VERSION "VUBR initial telemetry database"

NS_ :

BS_:

BU_: Vector__XXX AMS BMS VCU Inverter InverterCooling Precharge Dashboard PowerDistribution Pedalbox

BO_ 1 Error: 1 Vector__XXX
 SG_ error_code : 0|8@1+ (1,0) [0|255] "" Vector__XXX

BO_ 6 PrechargeStatus: 8 Precharge
 SG_ precharge_register M : 0|8@1+ (1,0) [0|255] "" Vector__XXX
 SG_ precharge_status m32 : 8|8@1+ (1,0) [0|255] "" Vector__XXX
 SG_ precharge_voltage_battery m48 : 8|8@1+ (1,0) [0|255] "V" Vector__XXX
 SG_ precharge_voltage_ts m64 : 8|8@1+ (1,0) [0|255] "V" Vector__XXX

BO_ 18 AppsAnalogValues: 8 VCU
 SG_ apps1_raw : 0|16@1+ (1,0) [0|65535] "" Vector__XXX
 SG_ apps2_raw : 16|16@1+ (1,0) [0|65535] "" Vector__XXX

BO_ 21 DashboardInfo: 1 Dashboard
 SG_ dashboard_event : 0|8@1+ (1,0) [0|255] "" Vector__XXX

BO_ 36 DtiSetAcCurrent: 8 Pedalbox
 SG_ inverter_cmd_target_ac_current : 7|16@0- (0.1,0) [-850|850] "A" Vector__XXX

BO_ 68 DtiSetBrakeCurrent: 8 Pedalbox
 SG_ inverter_cmd_target_brake_current : 7|16@0- (0.1,0) [0|850] "A" Vector__XXX

BO_ 100 DtiSetErpm: 4 Pedalbox
 SG_ inverter_cmd_target_speed : 7|32@0- (1,0) [-100000|100000] "ERPM" Vector__XXX

BO_ 132 DtiSetPosition: 2 Pedalbox
 SG_ inverter_cmd_target_position : 7|16@0- (0.1,0) [0|359] "deg" Vector__XXX

BO_ 164 DtiSetRelativeCurrent: 2 Pedalbox
 SG_ inverter_cmd_target_relative_current : 7|16@0- (0.1,0) [-100|100] "%" Vector__XXX

BO_ 196 DtiSetRelativeBrakeCurrent: 2 Pedalbox
 SG_ inverter_cmd_target_relative_brake_current : 7|16@0- (0.1,0) [0|100] "%" Vector__XXX

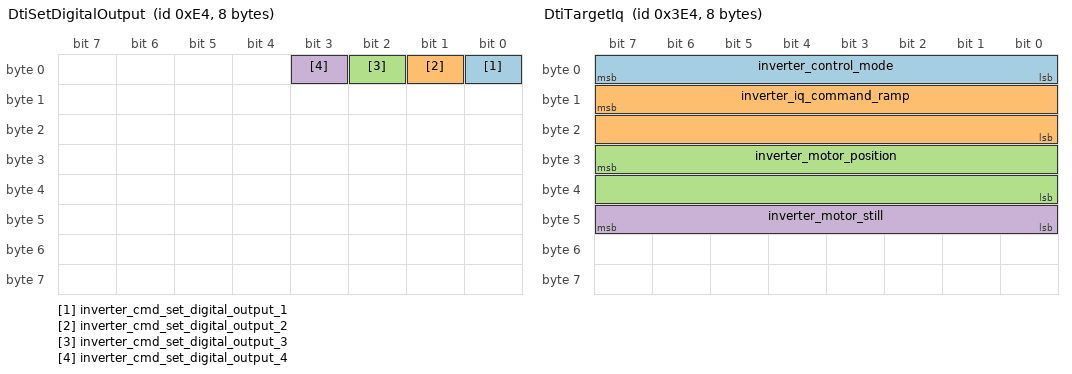
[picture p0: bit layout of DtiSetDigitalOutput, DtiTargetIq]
BO_ 228 DtiSetDigitalOutput: 8 Pedalbox
 SG_ inverter_cmd_set_digital_output_1 : 0|1@0+ (1,0) [0|1] "" Vector__XXX
 SG_ inverter_cmd_set_digital_output_2 : 1|1@0+ (1,0) [0|1] "" Vector__XXX
 SG_ inverter_cmd_set_digital_output_3 : 2|1@0+ (1,0) [0|1] "" Vector__XXX
 SG_ inverter_cmd_set_digital_output_4 : 3|1@0+ (1,0) [0|1] "" Vector__XXX

BO_ 260 DtiSetMaxAcCurrent: 2 Pedalbox
 SG_ inverter_cmd_max_ac_current : 7|16@0- (0.1,0) [0|850] "A" Vector__XXX

BO_ 292 DtiSetMaxAcBrakeCurrent: 2 Pedalbox
 SG_ inverter_cmd_max_ac_brake_current : 7|16@0- (0.1,0) [-850|0] "A" Vector__XXX

BO_ 324 DtiSetMaxDcCurrent: 2 Pedalbox
 SG_ inverter_cmd_max_dc_current : 7|16@0- (0.1,0) [0|850] "A" Vector__XXX

BO_ 356 DtiSetMaxDcBrakeCurrent: 2 Pedalbox
 SG_ inverter_cmd_max_dc_brake_current : 7|16@0- (0.1,0) [-850|0] "A" Vector__XXX

BO_ 388 DtiSetDriveEnable: 2 Pedalbox
 SG_ inverter_cmd_drive_enable : 7|8@0+ (1,0) [0|1] "" Vector__XXX

BO_ 996 DtiTargetIq: 8 Inverter
 SG_ inverter_control_mode : 7|8@0+ (1,0) [0|7] "" Vector__XXX
 SG_ inverter_iq_command_ramp : 15|16@0- (0.1,0) [-850|850] "A" Vector__XXX
 SG_ inverter_motor_position : 31|16@0+ (0.1,0) [0|359] "deg" Vector__XXX
 SG_ inverter_motor_still : 47|8@0+ (1,0) [0|1] "" Vector__XXX

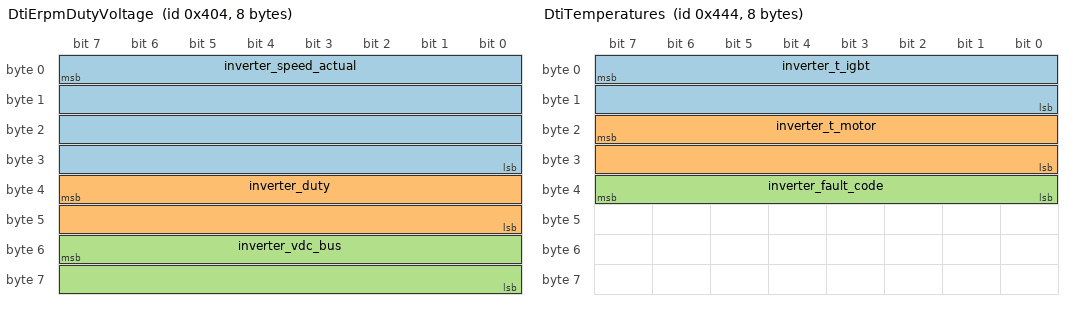
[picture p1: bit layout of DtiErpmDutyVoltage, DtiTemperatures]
BO_ 1028 DtiErpmDutyVoltage: 8 Inverter
 SG_ inverter_speed_actual : 7|32@0- (1,0) [-120000|120000] "ERPM" Vector__XXX
 SG_ inverter_duty : 39|16@0- (0.1,0) [-100|100] "%" Vector__XXX
 SG_ inverter_vdc_bus : 55|16@0- (1,0) [0|1000] "V" Vector__XXX

BO_ 1060 DtiAcDcCurrent: 8 Inverter
 SG_ inverter_ac_current : 7|16@0- (0.1,0) [-850|850] "A" Vector__XXX
 SG_ inverter_dc_current : 23|16@0- (0.1,0) [-850|850] "A" Vector__XXX

BO_ 1092 DtiTemperatures: 8 Inverter
 SG_ inverter_t_igbt : 7|16@0- (0.1,0) [-55|200] "degC" Vector__XXX
 SG_ inverter_t_motor : 23|16@0- (0.1,0) [-55|200] "degC" Vector__XXX
 SG_ inverter_fault_code : 39|8@0+ (1,0) [0|255] "" Vector__XXX

BO_ 1124 DtiFoc: 8 Inverter
 SG_ inverter_id_actual : 7|32@0- (0.01,0) [-850|850] "A" Vector__XXX
 SG_ inverter_iq_actual : 39|32@0- (0.01,0) [-850|850] "A" Vector__XXX

BO_ 1156 DtiMisc: 8 Inverter
 SG_ inverter_throttle : 7|8@0- (1,0) [0|100] "%" Vector__XXX
 SG_ inverter_brake : 15|8@0- (1,0) [0|100] "%" Vector__XXX
 SG_ inverter_digital_input_1 : 16|1@0+ (1,0) [0|1] "" Vector__XXX
 SG_ inverter_digital_input_2 : 17|1@0+ (1,0) [0|1] "" Vector__XXX
 SG_ inverter_digital_input_3 : 18|1@0+ (1,0) [0|1] "" Vector__XXX
 SG_ inverter_digital_input_4 : 19|1@0+ (1,0) [0|1] "" Vector__XXX
 SG_ inverter_digital_output_1 : 20|1@0+ (1,0) [0|1] "" Vector__XXX
 SG_ inverter_digital_output_2 : 21|1@0+ (1,0) [0|1] "" Vector__XXX
 SG_ inverter_digital_output_3 : 22|1@0+ (1,0) [0|1] "" Vector__XXX
 SG_ inverter_digital_output_4 : 23|1@0+ (1,0) [0|1] "" Vector__XXX
 SG_ inverter_drive_enable : 31|8@0+ (1,0) [0|1] "" Vector__XXX
 SG_ inverter_capacitor_temp_limit : 32|1@0+ (1,0) [0|1] "" Vector__XXX
 SG_ inverter_dc_current_limit : 33|1@0+ (1,0) [0|1] "" Vector__XXX
 SG_ inverter_drive_enable_limit : 34|1@0+ (1,0) [0|1] "" Vector__XXX
 SG_ inverter_igbt_accel_limit : 35|1@0+ (1,0) [0|1] "" Vector__XXX
 SG_ inverter_igbt_temp_limit : 36|1@0+ (1,0) [0|1] "" Vector__XXX
 SG_ inverter_input_voltage_limit : 37|1@0+ (1,0) [0|1] "" Vector__XXX
 SG_ inverter_motor_accel_limit : 38|1@0+ (1,0) [0|1] "" Vector__XXX
 SG_ inverter_motor_temp_limit : 39|1@0+ (1,0) [0|1] "" Vector__XXX
 SG_ inverter_rpm_min_limit : 40|1@0+ (1,0) [0|1] "" Vector__XXX
 SG_ inverter_rpm_max_limit : 41|1@0+ (1,0) [0|1] "" Vector__XXX
 SG_ inverter_power_limit : 42|1@0+ (1,0) [0|1] "" Vector__XXX
 SG_ inverter_can_map_version : 63|8@0+ (0.1,0) [0|255] "" Vector__XXX

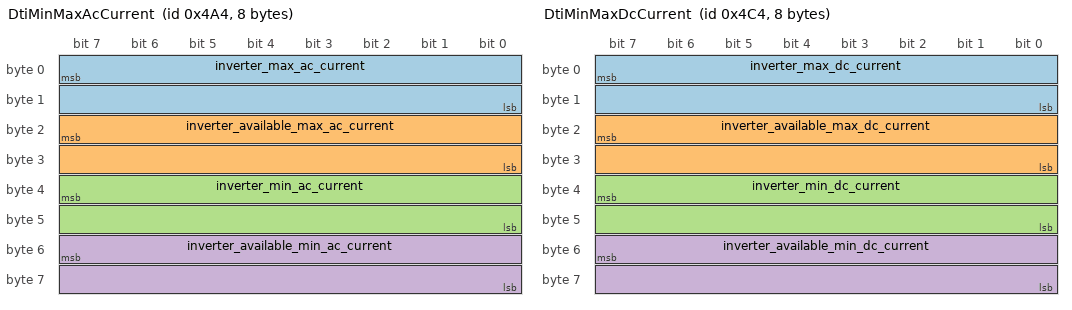
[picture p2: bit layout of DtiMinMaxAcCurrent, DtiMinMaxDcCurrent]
BO_ 1188 DtiMinMaxAcCurrent: 8 Inverter
 SG_ inverter_max_ac_current : 7|16@0- (0.1,0) [0|850] "A" Vector__XXX
 SG_ inverter_available_max_ac_current : 23|16@0- (0.1,0) [0|850] "A" Vector__XXX
 SG_ inverter_min_ac_current : 39|16@0- (0.1,0) [-850|0] "A" Vector__XXX
 SG_ inverter_available_min_ac_current : 55|16@0- (0.1,0) [-850|0] "A" Vector__XXX

BO_ 1220 DtiMinMaxDcCurrent: 8 Inverter
 SG_ inverter_max_dc_current : 7|16@0- (0.1,0) [0|850] "A" Vector__XXX
 SG_ inverter_available_max_dc_current : 23|16@0- (0.1,0) [0|850] "A" Vector__XXX
 SG_ inverter_min_dc_current : 39|16@0- (0.1,0) [-850|0] "A" Vector__XXX
 SG_ inverter_available_min_dc_current : 55|16@0- (0.1,0) [-850|0] "A" Vector__XXX

BO_ 768 UserStatus: 8 VCU
 SG_ user_register M : 0|8@1+ (1,0) [0|255] "" Vector__XXX
 SG_ user_brake m2 : 24|8@1+ (1,0) [0|255] "" Vector__XXX
 SG_ user_apps m2 : 8|16@1+ (1,0) [0|65535] "" Vector__XXX
 SG_ user_state m1 : 8|8@1+ (1,0) [0|255] "" Vector__XXX

BO_ 770 BRAKESENS1_AVAL_ID: 2 VCU
 SG_ brake_pressure_1 : 0|16@1+ (1,0) [0|65535] "raw" Vector__XXX

BO_ 771 BRAKESENS2_AVAL_ID: 2 VCU
 SG_ brake_pressure_2 : 0|16@1+ (1,0) [0|65535] "raw" Vector__XXX

BO_ 772 SdcStatus: 2 Vector__XXX
 SG_ sdc_index : 0|8@1+ (1,0) [0|255] "" Vector__XXX
 SG_ sdc_closed : 8|1@1+ (1,0) [0|1] "" Vector__XXX

BO_ 773 PedalboxStatus: 1 Pedalbox
 SG_ bspd_hard_braking : 0|1@1+ (1,0) [0|1] "" Vector__XXX

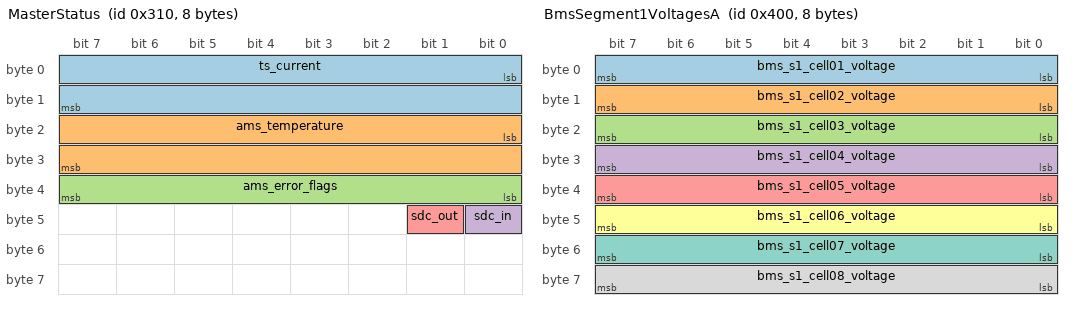
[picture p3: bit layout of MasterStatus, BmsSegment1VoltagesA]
BO_ 784 MasterStatus: 8 AMS
 SG_ ts_current : 0|16@1- (0.1,0) [-3276.8|3276.7] "A" Vector__XXX
 SG_ ams_temperature : 16|16@1- (0.1,0) [-3276.8|3276.7] "degC" Vector__XXX
 SG_ ams_error_flags : 32|8@1+ (1,0) [0|255] "" Vector__XXX
 SG_ sdc_in : 40|1@1+ (1,0) [0|1] "" Vector__XXX
 SG_ sdc_out : 41|1@1+ (1,0) [0|1] "" Vector__XXX

BO_ 1024 BmsSegment1VoltagesA: 8 AMS
 SG_ bms_s1_cell01_voltage : 0|8@1+ (0.01,2) [2|4.55] "V" Vector__XXX
 SG_ bms_s1_cell02_voltage : 8|8@1+ (0.01,2) [2|4.55] "V" Vector__XXX
 SG_ bms_s1_cell03_voltage : 16|8@1+ (0.01,2) [2|4.55] "V" Vector__XXX
 SG_ bms_s1_cell04_voltage : 24|8@1+ (0.01,2) [2|4.55] "V" Vector__XXX
 SG_ bms_s1_cell05_voltage : 32|8@1+ (0.01,2) [2|4.55] "V" Vector__XXX
 SG_ bms_s1_cell06_voltage : 40|8@1+ (0.01,2) [2|4.55] "V" Vector__XXX
 SG_ bms_s1_cell07_voltage : 48|8@1+ (0.01,2) [2|4.55] "V" Vector__XXX
 SG_ bms_s1_cell08_voltage : 56|8@1+ (0.01,2) [2|4.55] "V" Vector__XXX

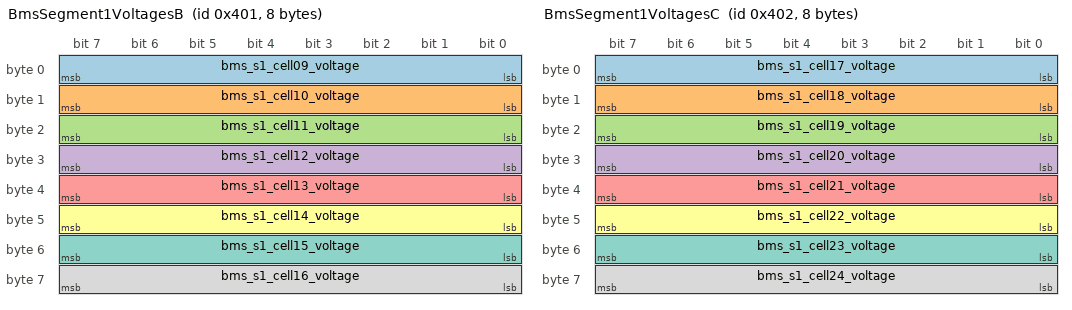
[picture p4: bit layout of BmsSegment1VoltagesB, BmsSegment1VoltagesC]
BO_ 1025 BmsSegment1VoltagesB: 8 AMS
 SG_ bms_s1_cell09_voltage : 0|8@1+ (0.01,2) [2|4.55] "V" Vector__XXX
 SG_ bms_s1_cell10_voltage : 8|8@1+ (0.01,2) [2|4.55] "V" Vector__XXX
 SG_ bms_s1_cell11_voltage : 16|8@1+ (0.01,2) [2|4.55] "V" Vector__XXX
 SG_ bms_s1_cell12_voltage : 24|8@1+ (0.01,2) [2|4.55] "V" Vector__XXX
 SG_ bms_s1_cell13_voltage : 32|8@1+ (0.01,2) [2|4.55] "V" Vector__XXX
 SG_ bms_s1_cell14_voltage : 40|8@1+ (0.01,2) [2|4.55] "V" Vector__XXX
 SG_ bms_s1_cell15_voltage : 48|8@1+ (0.01,2) [2|4.55] "V" Vector__XXX
 SG_ bms_s1_cell16_voltage : 56|8@1+ (0.01,2) [2|4.55] "V" Vector__XXX

BO_ 1026 BmsSegment1VoltagesC: 8 AMS
 SG_ bms_s1_cell17_voltage : 0|8@1+ (0.01,2) [2|4.55] "V" Vector__XXX
 SG_ bms_s1_cell18_voltage : 8|8@1+ (0.01,2) [2|4.55] "V" Vector__XXX
 SG_ bms_s1_cell19_voltage : 16|8@1+ (0.01,2) [2|4.55] "V" Vector__XXX
 SG_ bms_s1_cell20_voltage : 24|8@1+ (0.01,2) [2|4.55] "V" Vector__XXX
 SG_ bms_s1_cell21_voltage : 32|8@1+ (0.01,2) [2|4.55] "V" Vector__XXX
 SG_ bms_s1_cell22_voltage : 40|8@1+ (0.01,2) [2|4.55] "V" Vector__XXX
 SG_ bms_s1_cell23_voltage : 48|8@1+ (0.01,2) [2|4.55] "V" Vector__XXX
 SG_ bms_s1_cell24_voltage : 56|8@1+ (0.01,2) [2|4.55] "V" Vector__XXX

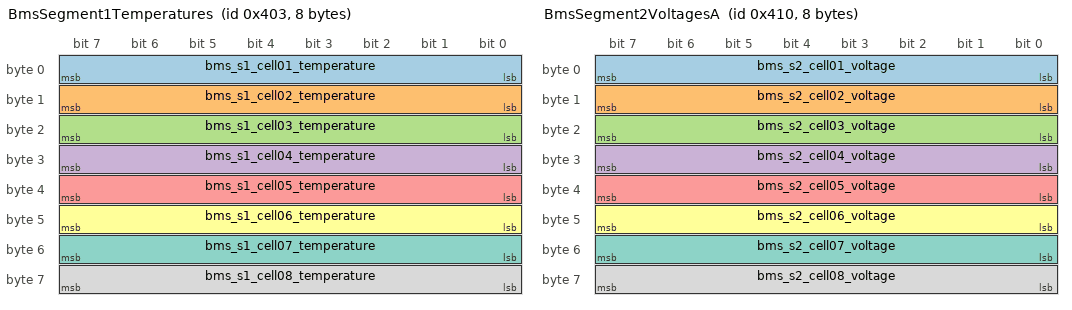
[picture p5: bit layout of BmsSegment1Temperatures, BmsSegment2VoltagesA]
BO_ 1027 BmsSegment1Temperatures: 8 AMS
 SG_ bms_s1_cell01_temperature : 0|8@1+ (0.5,-40) [-40|87.5] "degC" Vector__XXX
 SG_ bms_s1_cell02_temperature : 8|8@1+ (0.5,-40) [-40|87.5] "degC" Vector__XXX
 SG_ bms_s1_cell03_temperature : 16|8@1+ (0.5,-40) [-40|87.5] "degC" Vector__XXX
 SG_ bms_s1_cell04_temperature : 24|8@1+ (0.5,-40) [-40|87.5] "degC" Vector__XXX
 SG_ bms_s1_cell05_temperature : 32|8@1+ (0.5,-40) [-40|87.5] "degC" Vector__XXX
 SG_ bms_s1_cell06_temperature : 40|8@1+ (0.5,-40) [-40|87.5] "degC" Vector__XXX
 SG_ bms_s1_cell07_temperature : 48|8@1+ (0.5,-40) [-40|87.5] "degC" Vector__XXX
 SG_ bms_s1_cell08_temperature : 56|8@1+ (0.5,-40) [-40|87.5] "degC" Vector__XXX

BO_ 1029 BmsSegment1TemperaturesB: 2 AMS
 SG_ bms_s1_cell09_temperature : 0|8@1+ (0.5,-40) [-40|87.5] "degC" Vector__XXX
 SG_ bms_s1_cell10_temperature : 8|8@1+ (0.5,-40) [-40|87.5] "degC" Vector__XXX

BO_ 1040 BmsSegment2VoltagesA: 8 AMS
 SG_ bms_s2_cell01_voltage : 0|8@1+ (0.01,2) [2|4.55] "V" Vector__XXX
 SG_ bms_s2_cell02_voltage : 8|8@1+ (0.01,2) [2|4.55] "V" Vector__XXX
 SG_ bms_s2_cell03_voltage : 16|8@1+ (0.01,2) [2|4.55] "V" Vector__XXX
 SG_ bms_s2_cell04_voltage : 24|8@1+ (0.01,2) [2|4.55] "V" Vector__XXX
 SG_ bms_s2_cell05_voltage : 32|8@1+ (0.01,2) [2|4.55] "V" Vector__XXX
 SG_ bms_s2_cell06_voltage : 40|8@1+ (0.01,2) [2|4.55] "V" Vector__XXX
 SG_ bms_s2_cell07_voltage : 48|8@1+ (0.01,2) [2|4.55] "V" Vector__XXX
 SG_ bms_s2_cell08_voltage : 56|8@1+ (0.01,2) [2|4.55] "V" Vector__XXX

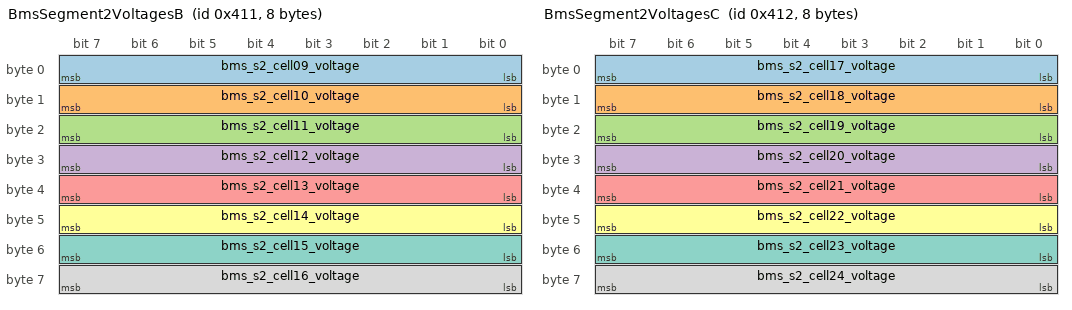
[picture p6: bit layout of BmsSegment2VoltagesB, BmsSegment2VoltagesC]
BO_ 1041 BmsSegment2VoltagesB: 8 AMS
 SG_ bms_s2_cell09_voltage : 0|8@1+ (0.01,2) [2|4.55] "V" Vector__XXX
 SG_ bms_s2_cell10_voltage : 8|8@1+ (0.01,2) [2|4.55] "V" Vector__XXX
 SG_ bms_s2_cell11_voltage : 16|8@1+ (0.01,2) [2|4.55] "V" Vector__XXX
 SG_ bms_s2_cell12_voltage : 24|8@1+ (0.01,2) [2|4.55] "V" Vector__XXX
 SG_ bms_s2_cell13_voltage : 32|8@1+ (0.01,2) [2|4.55] "V" Vector__XXX
 SG_ bms_s2_cell14_voltage : 40|8@1+ (0.01,2) [2|4.55] "V" Vector__XXX
 SG_ bms_s2_cell15_voltage : 48|8@1+ (0.01,2) [2|4.55] "V" Vector__XXX
 SG_ bms_s2_cell16_voltage : 56|8@1+ (0.01,2) [2|4.55] "V" Vector__XXX

BO_ 1042 BmsSegment2VoltagesC: 8 AMS
 SG_ bms_s2_cell17_voltage : 0|8@1+ (0.01,2) [2|4.55] "V" Vector__XXX
 SG_ bms_s2_cell18_voltage : 8|8@1+ (0.01,2) [2|4.55] "V" Vector__XXX
 SG_ bms_s2_cell19_voltage : 16|8@1+ (0.01,2) [2|4.55] "V" Vector__XXX
 SG_ bms_s2_cell20_voltage : 24|8@1+ (0.01,2) [2|4.55] "V" Vector__XXX
 SG_ bms_s2_cell21_voltage : 32|8@1+ (0.01,2) [2|4.55] "V" Vector__XXX
 SG_ bms_s2_cell22_voltage : 40|8@1+ (0.01,2) [2|4.55] "V" Vector__XXX
 SG_ bms_s2_cell23_voltage : 48|8@1+ (0.01,2) [2|4.55] "V" Vector__XXX
 SG_ bms_s2_cell24_voltage : 56|8@1+ (0.01,2) [2|4.55] "V" Vector__XXX

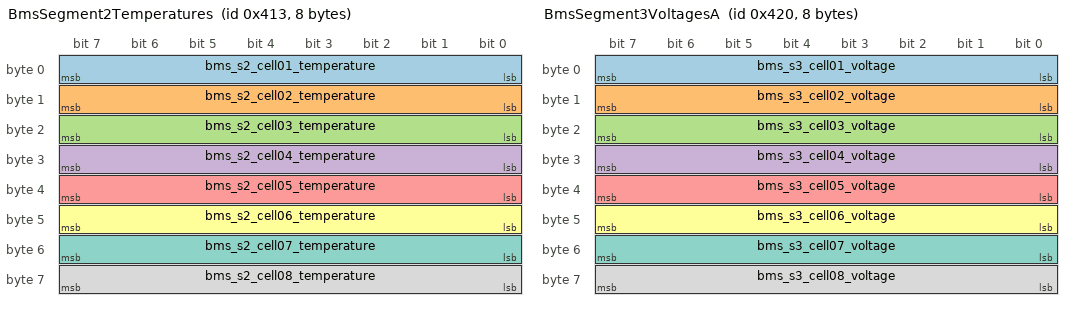
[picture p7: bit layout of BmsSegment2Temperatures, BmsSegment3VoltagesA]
BO_ 1043 BmsSegment2Temperatures: 8 AMS
 SG_ bms_s2_cell01_temperature : 0|8@1+ (0.5,-40) [-40|87.5] "degC" Vector__XXX
 SG_ bms_s2_cell02_temperature : 8|8@1+ (0.5,-40) [-40|87.5] "degC" Vector__XXX
 SG_ bms_s2_cell03_temperature : 16|8@1+ (0.5,-40) [-40|87.5] "degC" Vector__XXX
 SG_ bms_s2_cell04_temperature : 24|8@1+ (0.5,-40) [-40|87.5] "degC" Vector__XXX
 SG_ bms_s2_cell05_temperature : 32|8@1+ (0.5,-40) [-40|87.5] "degC" Vector__XXX
 SG_ bms_s2_cell06_temperature : 40|8@1+ (0.5,-40) [-40|87.5] "degC" Vector__XXX
 SG_ bms_s2_cell07_temperature : 48|8@1+ (0.5,-40) [-40|87.5] "degC" Vector__XXX
 SG_ bms_s2_cell08_temperature : 56|8@1+ (0.5,-40) [-40|87.5] "degC" Vector__XXX

BO_ 1045 BmsSegment2TemperaturesB: 2 AMS
 SG_ bms_s2_cell09_temperature : 0|8@1+ (0.5,-40) [-40|87.5] "degC" Vector__XXX
 SG_ bms_s2_cell10_temperature : 8|8@1+ (0.5,-40) [-40|87.5] "degC" Vector__XXX

BO_ 1056 BmsSegment3VoltagesA: 8 AMS
 SG_ bms_s3_cell01_voltage : 0|8@1+ (0.01,2) [2|4.55] "V" Vector__XXX
 SG_ bms_s3_cell02_voltage : 8|8@1+ (0.01,2) [2|4.55] "V" Vector__XXX
 SG_ bms_s3_cell03_voltage : 16|8@1+ (0.01,2) [2|4.55] "V" Vector__XXX
 SG_ bms_s3_cell04_voltage : 24|8@1+ (0.01,2) [2|4.55] "V" Vector__XXX
 SG_ bms_s3_cell05_voltage : 32|8@1+ (0.01,2) [2|4.55] "V" Vector__XXX
 SG_ bms_s3_cell06_voltage : 40|8@1+ (0.01,2) [2|4.55] "V" Vector__XXX
 SG_ bms_s3_cell07_voltage : 48|8@1+ (0.01,2) [2|4.55] "V" Vector__XXX
 SG_ bms_s3_cell08_voltage : 56|8@1+ (0.01,2) [2|4.55] "V" Vector__XXX

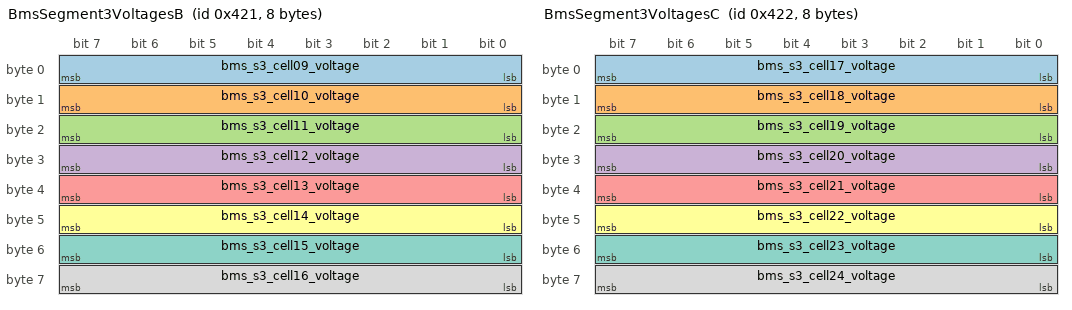
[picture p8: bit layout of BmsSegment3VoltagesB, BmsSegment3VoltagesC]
BO_ 1057 BmsSegment3VoltagesB: 8 AMS
 SG_ bms_s3_cell09_voltage : 0|8@1+ (0.01,2) [2|4.55] "V" Vector__XXX
 SG_ bms_s3_cell10_voltage : 8|8@1+ (0.01,2) [2|4.55] "V" Vector__XXX
 SG_ bms_s3_cell11_voltage : 16|8@1+ (0.01,2) [2|4.55] "V" Vector__XXX
 SG_ bms_s3_cell12_voltage : 24|8@1+ (0.01,2) [2|4.55] "V" Vector__XXX
 SG_ bms_s3_cell13_voltage : 32|8@1+ (0.01,2) [2|4.55] "V" Vector__XXX
 SG_ bms_s3_cell14_voltage : 40|8@1+ (0.01,2) [2|4.55] "V" Vector__XXX
 SG_ bms_s3_cell15_voltage : 48|8@1+ (0.01,2) [2|4.55] "V" Vector__XXX
 SG_ bms_s3_cell16_voltage : 56|8@1+ (0.01,2) [2|4.55] "V" Vector__XXX

BO_ 1058 BmsSegment3VoltagesC: 8 AMS
 SG_ bms_s3_cell17_voltage : 0|8@1+ (0.01,2) [2|4.55] "V" Vector__XXX
 SG_ bms_s3_cell18_voltage : 8|8@1+ (0.01,2) [2|4.55] "V" Vector__XXX
 SG_ bms_s3_cell19_voltage : 16|8@1+ (0.01,2) [2|4.55] "V" Vector__XXX
 SG_ bms_s3_cell20_voltage : 24|8@1+ (0.01,2) [2|4.55] "V" Vector__XXX
 SG_ bms_s3_cell21_voltage : 32|8@1+ (0.01,2) [2|4.55] "V" Vector__XXX
 SG_ bms_s3_cell22_voltage : 40|8@1+ (0.01,2) [2|4.55] "V" Vector__XXX
 SG_ bms_s3_cell23_voltage : 48|8@1+ (0.01,2) [2|4.55] "V" Vector__XXX
 SG_ bms_s3_cell24_voltage : 56|8@1+ (0.01,2) [2|4.55] "V" Vector__XXX

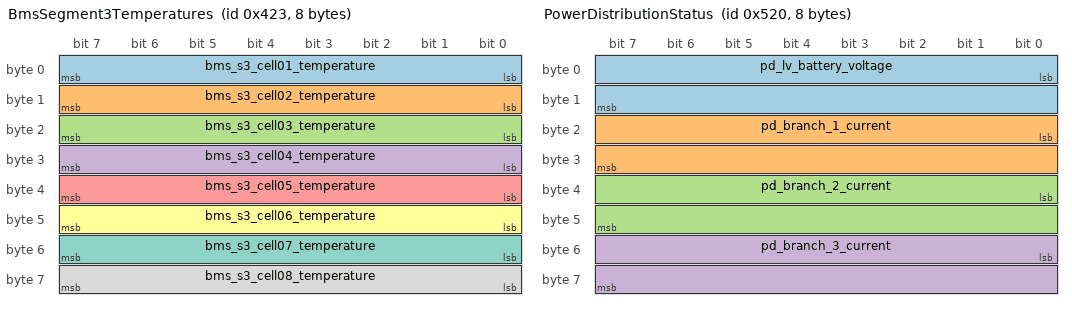
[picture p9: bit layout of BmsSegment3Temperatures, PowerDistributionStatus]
BO_ 1059 BmsSegment3Temperatures: 8 AMS
 SG_ bms_s3_cell01_temperature : 0|8@1+ (0.5,-40) [-40|87.5] "degC" Vector__XXX
 SG_ bms_s3_cell02_temperature : 8|8@1+ (0.5,-40) [-40|87.5] "degC" Vector__XXX
 SG_ bms_s3_cell03_temperature : 16|8@1+ (0.5,-40) [-40|87.5] "degC" Vector__XXX
 SG_ bms_s3_cell04_temperature : 24|8@1+ (0.5,-40) [-40|87.5] "degC" Vector__XXX
 SG_ bms_s3_cell05_temperature : 32|8@1+ (0.5,-40) [-40|87.5] "degC" Vector__XXX
 SG_ bms_s3_cell06_temperature : 40|8@1+ (0.5,-40) [-40|87.5] "degC" Vector__XXX
 SG_ bms_s3_cell07_temperature : 48|8@1+ (0.5,-40) [-40|87.5] "degC" Vector__XXX
 SG_ bms_s3_cell08_temperature : 56|8@1+ (0.5,-40) [-40|87.5] "degC" Vector__XXX

BO_ 1061 BmsSegment3TemperaturesB: 2 AMS
 SG_ bms_s3_cell09_temperature : 0|8@1+ (0.5,-40) [-40|87.5] "degC" Vector__XXX
 SG_ bms_s3_cell10_temperature : 8|8@1+ (0.5,-40) [-40|87.5] "degC" Vector__XXX

BO_ 1120 InverterCoolingStatus: 8 InverterCooling
 SG_ inverter_cooling_register M : 0|8@1+ (1,0) [0|255] "" Vector__XXX
 SG_ inverter_cooling_temp_1 m1 : 8|16@1- (0.1,0) [-3276.8|3276.7] "degC" Vector__XXX
 SG_ inverter_cooling_temp_2 m1 : 24|16@1- (0.1,0) [-3276.8|3276.7] "degC" Vector__XXX
 SG_ inverter_cooling_pump_duty m2 : 8|8@1+ (1,0) [0|100] "%" Vector__XXX
 SG_ inverter_cooling_vent_duty m2 : 16|8@1+ (1,0) [0|100] "%" Vector__XXX

BO_ 1312 PowerDistributionStatus: 8 PowerDistribution
 SG_ pd_lv_battery_voltage : 0|16@1+ (0.01,0) [0|20] "V" Vector__XXX
 SG_ pd_branch_1_current : 16|16@1+ (0.01,0) [0|655.35] "A" Vector__XXX
 SG_ pd_branch_2_current : 32|16@1+ (0.01,0) [0|655.35] "A" Vector__XXX
 SG_ pd_branch_3_current : 48|16@1+ (0.01,0) [0|655.35] "A" Vector__XXX

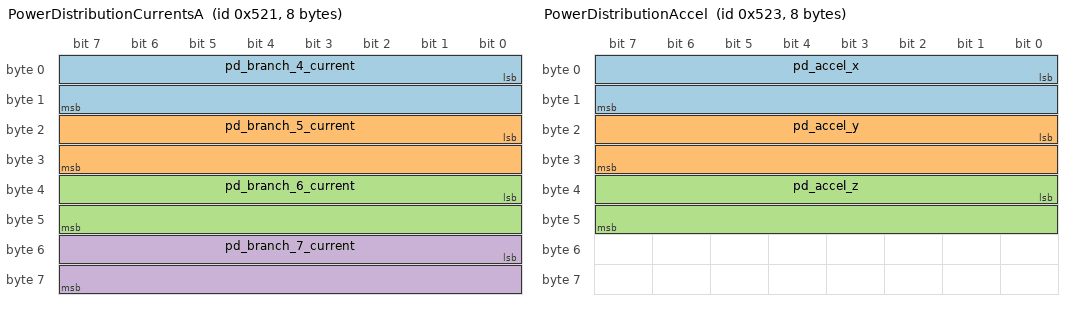
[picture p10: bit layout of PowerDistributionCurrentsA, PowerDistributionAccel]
BO_ 1313 PowerDistributionCurrentsA: 8 PowerDistribution
 SG_ pd_branch_4_current : 0|16@1+ (0.01,0) [0|655.35] "A" Vector__XXX
 SG_ pd_branch_5_current : 16|16@1+ (0.01,0) [0|655.35] "A" Vector__XXX
 SG_ pd_branch_6_current : 32|16@1+ (0.01,0) [0|655.35] "A" Vector__XXX
 SG_ pd_branch_7_current : 48|16@1+ (0.01,0) [0|655.35] "A" Vector__XXX

BO_ 1314 PowerDistributionCurrentsB: 8 PowerDistribution
 SG_ pd_branch_8_current : 0|16@1+ (0.01,0) [0|655.35] "A" Vector__XXX
 SG_ pd_branch_9_current : 16|16@1+ (0.01,0) [0|655.35] "A" Vector__XXX

BO_ 1315 PowerDistributionAccel: 8 PowerDistribution
 SG_ pd_accel_x : 0|16@1- (0.001,0) [-32.768|32.767] "g" Vector__XXX
 SG_ pd_accel_y : 16|16@1- (0.001,0) [-32.768|32.767] "g" Vector__XXX
 SG_ pd_accel_z : 32|16@1- (0.001,0) [-32.768|32.767] "g" Vector__XXX

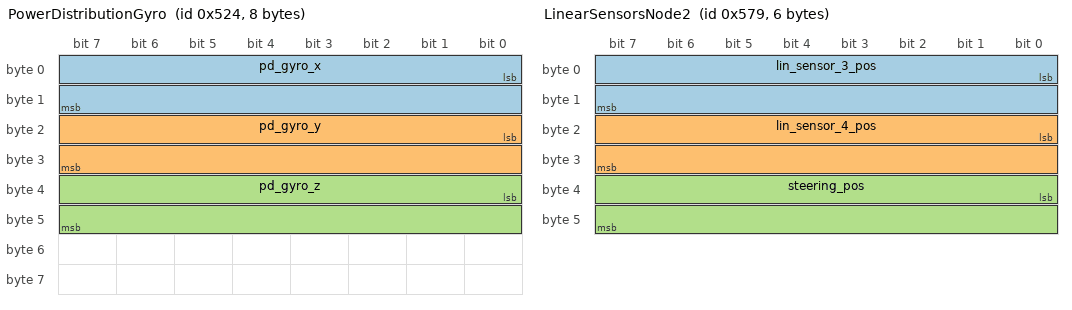
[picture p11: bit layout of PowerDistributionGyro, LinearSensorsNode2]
BO_ 1316 PowerDistributionGyro: 8 PowerDistribution
 SG_ pd_gyro_x : 0|16@1- (0.01,0) [-327.68|327.67] "deg/s" Vector__XXX
 SG_ pd_gyro_y : 16|16@1- (0.01,0) [-327.68|327.67] "deg/s" Vector__XXX
 SG_ pd_gyro_z : 32|16@1- (0.01,0) [-327.68|327.67] "deg/s" Vector__XXX

BO_ 1400 LinearSensorsNode1: 4 FeatherRP2040_1
  SG_ lin_sensor_1_pos : 0|16@1- (0.01,0) [-50|50] "mm" Vector__XXX
  SG_ lin_sensor_2_pos : 16|16@1- (0.01,0) [-50|50] "mm" Vector__XXX

BO_ 1401 LinearSensorsNode2: 6 FeatherRP2040_2
  SG_ lin_sensor_3_pos : 0|16@1- (0.01,0) [-50|50] "mm" Vector__XXX
  SG_ lin_sensor_4_pos : 16|16@1- (0.01,0) [-50|50] "mm" Vector__XXX
  SG_ steering_pos : 32|16@1- (0.01,0) [-50|50] "mm" Vector__XXX

VAL_ 21 dashboard_event 1 "R2D button on" 2 "R2D switch on" 3 "R2D switch off" 4 "SW1 on" 5 "SW1 off" 6 "SW2 on" 7 "SW2 off";
VAL_ 768 user_state 1 "off" 2 "before_precharge" 3 "precharge" 4 "after_precharge" 5 "calibration_min" 6 "calibration_max" 7 "last_step" 8 "on" 9 "test" 16 "bspd";
VAL_ 772 sdc_index 1 "dashboard" 2 "pedalbox" 3 "ams_in" 4 "ams_out" 5 "precharge_end";
